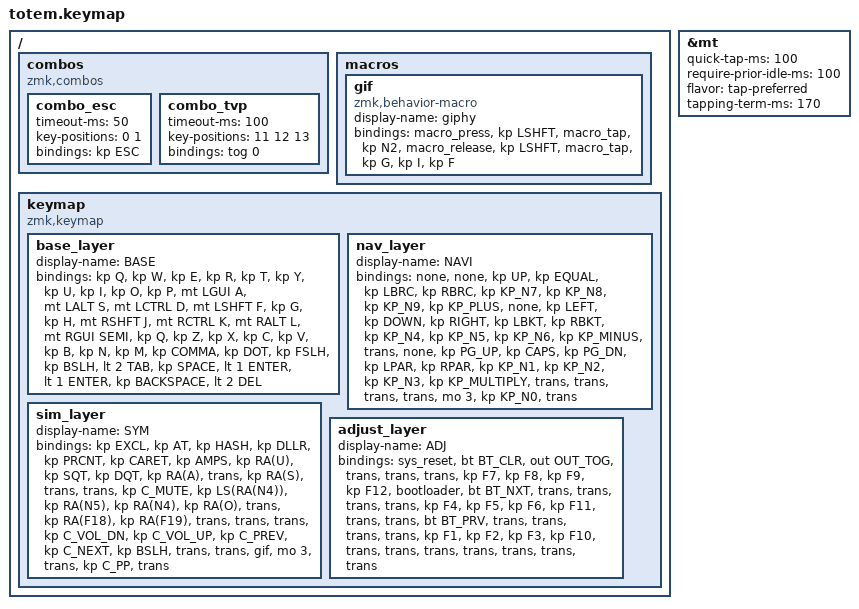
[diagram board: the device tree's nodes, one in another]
#include <behaviors.dtsi>
#include <dt-bindings/zmk/bt.h>
#include <dt-bindings/zmk/keys.h>
#include <dt-bindings/zmk/outputs.h>

#define BASE 0
#define NAV  1
#define SYM  2
#define ADJ  3
#define TVP1 4
#define TVP2 5

&mt {
    quick-tap-ms = <100>;
    require-prior-idle-ms = <100>;
    flavor = "tap-preferred";
    tapping-term-ms = <170>;
};

/ {
    combos {
        compatible = "zmk,combos";

        combo_esc {
            timeout-ms = <50>;
            key-positions = <0 1>;
            bindings = <&kp ESC>;
        };

        combo_tvp {
            timeout-ms = <100>;
            key-positions = <11 12 13>;
            bindings = <&tog 0>;
        };
    };

    macros {
        gif: gif {
            display-name = "giphy";
            compatible = "zmk,behavior-macro";
            #binding-cells = <0>;
            bindings =
                <&macro_press>,
                <&kp LSHFT>,
                <&macro_tap>,
                <&kp N2>,
                <&macro_release>,
                <&kp LSHFT>,
                <&macro_tap>,
                <&kp G &kp I &kp F>;
        };
    };

    keymap {
        compatible = "zmk,keymap";

        // ▄▄▄▄▄▄▄▄▄▄▄▄▄▄▄▄▄▄▄▄▄▄▄▄▄▄▄▄▄▄▄▄▄▄▄▄▄▄▄▄▄▄▄▄▄▄▄▄▄▄▄▄▄▄▄▄▄▄▄▄▄▄▄▄▄▄▄▄▄▄▄▄▄▄▄▄▄▄▄▄▄▄▄▄▄▄▄▄▄▄▄▄▄▄▄▄▄▄▄▄▄▄▄▄▄▄▄▄▄▄▄▄▄▄▄▄▄▄▄▄▄▄▄▄▄▄▄▄▄▄▄▄▄▄▄▄▄▄▄▄▄▄▄▄▄▄▄▄▄

        base_layer {
            // ┏━━━━━━━━━━━━━━━━━━━━━━━━━━━━━━━━━━━━━━━┓

            display-name = "BASE";

            // ┗━━━━━━━━━━━━━━━━━━━━━━━━━━━━━━━━━━━━━━━┛
            //             ┏━━━━━━━━━━━┳━━━━━━━━━━━┳━━━━━━━━━━━┳━━━━━━━━━━━┳━━━━━━━━━━━┓   ┏━━━━━━━━━━━┳━━━━━━━━━━━┳━━━━━━━━━━━┳━━━━━━━━━━━┳━━━━━━━━━━━┓
            //             ┃     Q     ┃     W     ┃     E     ┃     R     ┃     T     ┃   ┃     Y     ┃     U     ┃     I     ┃     O     ┃     P     ┃
            //             ┣━━━━━━━━━━━╋━━━━━━━━━━━╋━━━━━━━━━━━╋━━━━━━━━━━━╋━━━━━━━━━━━┫   ┣━━━━━━━━━━━╋━━━━━━━━━━━╋━━━━━━━━━━━╋━━━━━━━━━━━╋━━━━━━━━━━━┫
            //             ┃     A     ┃     S     ┃     D     ┃     F     ┃     G     ┃   ┃     H     ┃     J     ┃     K     ┃     L     ┃     ;     ┃
            // ┏━━━━━━━━━━━╋━━━━━━━━━━━╋━━━━━━━━━━━╋━━━━━━━━━━━╋━━━━━━━━━━━╋━━━━━━━━━━━┫   ┣━━━━━━━━━━━╋━━━━━━━━━━━╋━━━━━━━━━━━╋━━━━━━━━━━━╋━━━━━━━━━━━╋━━━━━━━━━━━┓
            // ┃     Q     ┃     Z     ┃     X     ┃     C     ┃     V     ┃     B     ┃   ┃     N     ┃     M     ┃     ,     ┃     .     ┃     /     ┃     \     ┃
            // ┗━━━━━━━━━━━┻━━━━━━━━━━━┻━━━━━━━━━━━╋━━━━━━━━━━━╋━━━━━━━━━━━╋━━━━━━━━━━━┫   ┣━━━━━━━━━━━╋━━━━━━━━━━━╋━━━━━━━━━━━╋━━━━━━━━━━━┻━━━━━━━━━━━┻━━━━━━━━━━━┛
            //                                     ┃    DEL    ┃    TAB    ┃    SPC    ┃   ┃   ENTER   ┃           ┃   BSPC    ┃
            //                                     ┗━━━━━━━━━━━┻━━━━━━━━━━━┻━━━━━━━━━━━┛   ┗━━━━━━━━━━━┻━━━━━━━━━━━┻━━━━━━━━━━━┛

            bindings = <
&kp Q  &kp W  &kp E  &kp R  &kp T  &kp Y  &kp U  &kp I  &kp O  &kp P  &mt LGUI A  &mt LALT S  &mt LCTRL D  &mt LSHFT F  &kp G  &kp H  &mt RSHFT J  &mt RCTRL K  &mt RALT L  &mt RGUI SEMI  &kp Q  &kp Z  &kp X  &kp C  &kp V  &kp B  &kp N  &kp M  &kp COMMA  &kp DOT  &kp FSLH  &kp BSLH  &lt 2 TAB  &kp SPACE  &lt 1 ENTER  &lt 1 ENTER  &kp BACKSPACE  &lt 2 DEL
            >;
        };

        // ▄▄▄▄▄▄▄▄▄▄▄▄▄▄▄▄▄▄▄▄▄▄▄▄▄▄▄▄▄▄▄▄▄▄▄▄▄▄▄▄▄▄▄▄▄▄▄▄▄▄▄▄▄▄▄▄▄▄▄▄▄▄▄▄▄▄▄▄▄▄▄▄▄▄▄▄▄▄▄▄▄▄▄▄▄▄▄▄▄▄▄▄▄▄▄▄▄▄▄▄▄▄▄▄▄▄▄▄▄▄▄▄▄▄▄▄▄▄▄▄▄▄▄▄▄▄▄▄▄▄▄▄▄▄▄▄▄▄▄▄▄▄▄▄▄▄▄▄▄

        nav_layer {
            // ┏━━━━━━━━━━━━━━━━━━━━━━━━━━━━━━━━━━━━━━━┓

            display-name = "NAVI";

            // ┗━━━━━━━━━━━━━━━━━━━━━━━━━━━━━━━━━━━━━━━┛
            //             ┏━━━━━━━━━━━┳━━━━━━━━━━━┳━━━━━━━━━━━┳━━━━━━━━━━━┳━━━━━━━━━━━┓   ┏━━━━━━━━━━━┳━━━━━━━━━━━┳━━━━━━━━━━━┳━━━━━━━━━━━┳━━━━━━━━━━━┓
            //             ┃           ┃           ┃     UP    ┃           ┃     {     ┃   ┃     }     ┃     7     ┃     8     ┃     9     ┃     +     ┃
            //             ┣━━━━━━━━━━━╋━━━━━━━━━━━╋━━━━━━━━━━━╋━━━━━━━━━━━╋━━━━━━━━━━━┫   ┣━━━━━━━━━━━╋━━━━━━━━━━━╋━━━━━━━━━━━╋━━━━━━━━━━━╋━━━━━━━━━━━┫
            //             ┃   SHIFT   ┃   LEFT    ┃    DOWN   ┃   RIGHT   ┃     [     ┃   ┃     ]     ┃     4     ┃     5     ┃     6     ┃     -     ┃
            // ┏━━━━━━━━━━━╋━━━━━━━━━━━╋━━━━━━━━━━━╋━━━━━━━━━━━╋━━━━━━━━━━━╋━━━━━━━━━━━┫   ┣━━━━━━━━━━━╋━━━━━━━━━━━╋━━━━━━━━━━━╋━━━━━━━━━━━╋━━━━━━━━━━━╋━━━━━━━━━━━┓
            // ┃           ┃           ┃   P UP    ┃  C LOCK   ┃  P DOWN   ┃     (     ┃   ┃     )     ┃     1     ┃     2     ┃     3     ┃     *     ┃           ┃
            // ┗━━━━━━━━━━━┻━━━━━━━━━━━┻━━━━━━━━━━━╋━━━━━━━━━━━╋━━━━━━━━━━━╋━━━━━━━━━━━┫   ┣━━━━━━━━━━━╋━━━━━━━━━━━╋━━━━━━━━━━━╋━━━━━━━━━━━┻━━━━━━━━━━━┻━━━━━━━━━━━┛
            //                                     ┃           ┃    TAB    ┃    SPC    ┃   ┃    DEL    ┃     0     ┃           ┃
            //                                     ┗━━━━━━━━━━━┻━━━━━━━━━━━┻━━━━━━━━━━━┛   ┗━━━━━━━━━━━┻━━━━━━━━━━━┻━━━━━━━━━━━┛

            bindings = <
&none  &none  &kp UP  &kp EQUAL  &kp LBRC  &kp RBRC  &kp KP_N7  &kp KP_N8  &kp KP_N9  &kp KP_PLUS  &none  &kp LEFT  &kp DOWN  &kp RIGHT  &kp LBKT  &kp RBKT  &kp KP_N4  &kp KP_N5  &kp KP_N6  &kp KP_MINUS  &trans  &none  &kp PG_UP  &kp CAPS  &kp PG_DN  &kp LPAR  &kp RPAR  &kp KP_N1  &kp KP_N2  &kp KP_N3  &kp KP_MULTIPLY  &trans  &trans  &trans  &trans  &mo 3  &kp KP_N0  &trans
            >;
        };

        // ▄▄▄▄▄▄▄▄▄▄▄▄▄▄▄▄▄▄▄▄▄▄▄▄▄▄▄▄▄▄▄▄▄▄▄▄▄▄▄▄▄▄▄▄▄▄▄▄▄▄▄▄▄▄▄▄▄▄▄▄▄▄▄▄▄▄▄▄▄▄▄▄▄▄▄▄▄▄▄▄▄▄▄▄▄▄▄▄▄▄▄▄▄▄▄▄▄▄▄▄▄▄▄▄▄▄▄▄▄▄▄▄▄▄▄▄▄▄▄▄▄▄▄▄▄▄▄▄▄▄▄▄▄▄▄▄▄▄▄▄▄▄▄▄▄▄▄▄▄

        sim_layer {
            // ┏━━━━━━━━━━━━━━━━━━━━━━━━━━━━━━━━━━━━━━━┓

            display-name = "SYM";

            // ┗━━━━━━━━━━━━━━━━━━━━━━━━━━━━━━━━━━━━━━━┛
            //             ┏━━━━━━━━━━━┳━━━━━━━━━━━┳━━━━━━━━━━━┳━━━━━━━━━━━┳━━━━━━━━━━━┓   ┏━━━━━━━━━━━┳━━━━━━━━━━━┳━━━━━━━━━━━┳━━━━━━━━━━━┳━━━━━━━━━━━┓
            //             ┃     !     ┃     @     ┃     #     ┃     $     ┃     %     ┃   ┃     ˆ     ┃     &     ┃     Ü     ┃     '     ┃     "     ┃
            //             ┣━━━━━━━━━━━╋━━━━━━━━━━━╋━━━━━━━━━━━╋━━━━━━━━━━━╋━━━━━━━━━━━┫   ┣━━━━━━━━━━━╋━━━━━━━━━━━╋━━━━━━━━━━━╋━━━━━━━━━━━╋━━━━━━━━━━━┫
            //             ┃     Ä     ┃           ┃    SZ     ┃           ┃           ┃   ┃   MUTE    ┃   YEN     ┃   EURO    ┃  POUND    ┃     Ö     ┃
            // ┏━━━━━━━━━━━╋━━━━━━━━━━━╋━━━━━━━━━━━╋━━━━━━━━━━━╋━━━━━━━━━━━╋━━━━━━━━━━━┫   ┣━━━━━━━━━━━╋━━━━━━━━━━━╋━━━━━━━━━━━╋━━━━━━━━━━━╋━━━━━━━━━━━╋━━━━━━━━━━━┓
            // ┃           ┃  EMAIL1   ┃  EMAIL2   ┃           ┃           ┃           ┃   ┃   VOL-    ┃   VOL+    ┃   LAST    ┃   NEXT    ┃     \     ┃           ┃
            // ┗━━━━━━━━━━━┻━━━━━━━━━━━┻━━━━━━━━━━━╋━━━━━━━━━━━╋━━━━━━━━━━━╋━━━━━━━━━━━┫   ┣━━━━━━━━━━━╋━━━━━━━━━━━╋━━━━━━━━━━━╋━━━━━━━━━━━┻━━━━━━━━━━━┻━━━━━━━━━━━┛
            //                                     ┃           ┃    GIF    ┃    ADJ    ┃   ┃           ┃           ┃           ┃
            //                                     ┗━━━━━━━━━━━┻━━━━━━━━━━━┻━━━━━━━━━━━┛   ┗━━━━━━━━━━━┻━━━━━━━━━━━┻━━━━━━━━━━━┛

            bindings = <
&kp EXCL  &kp AT  &kp HASH  &kp DLLR  &kp PRCNT  &kp CARET  &kp AMPS  &kp RA(U)  &kp SQT  &kp DQT  &kp RA(A)  &trans  &kp RA(S)  &trans  &trans  &kp C_MUTE  &kp LS(RA(N4))  &kp RA(N5)  &kp RA(N4)  &kp RA(O)  &trans  &kp RA(F18)  &kp RA(F19)  &trans  &trans  &trans  &kp C_VOL_DN  &kp C_VOL_UP  &kp C_PREV  &kp C_NEXT  &kp BSLH  &trans  &trans  &gif  &mo 3  &trans  &kp C_PP  &trans
            >;
        };

        // ▄▄▄▄▄▄▄▄▄▄▄▄▄▄▄▄▄▄▄▄▄▄▄▄▄▄▄▄▄▄▄▄▄▄▄▄▄▄▄▄▄▄▄▄▄▄▄▄▄▄▄▄▄▄▄▄▄▄▄▄▄▄▄▄▄▄▄▄▄▄▄▄▄▄▄▄▄▄▄▄▄▄▄▄▄▄▄▄▄▄▄▄▄▄▄▄▄▄▄▄▄▄▄▄▄▄▄▄▄▄▄▄▄▄▄▄▄▄▄▄▄▄▄▄▄▄▄▄▄▄▄▄▄▄▄▄▄▄▄▄▄▄▄▄▄▄▄▄▄

        adjust_layer {
            // ┏━━━━━━━━━━━━━━━━━━━━━━━━━━━━━━━━━━━━━━━┓

            display-name = "ADJ";

            // ┗━━━━━━━━━━━━━━━━━━━━━━━━━━━━━━━━━━━━━━━┛
            //             ┏━━━━━━━━━━━┳━━━━━━━━━━━┳━━━━━━━━━━━┳━━━━━━━━━━━┳━━━━━━━━━━━┓   ┏━━━━━━━━━━━┳━━━━━━━━━━━┳━━━━━━━━━━━┳━━━━━━━━━━━┳━━━━━━━━━━━┓
            //             ┃   RESET   ┃ BT CLEAR  ┃  OUT TOG  ┃           ┃           ┃   ┃           ┃    F7     ┃    F8     ┃    F9     ┃    F12    ┃
            //             ┣━━━━━━━━━━━╋━━━━━━━━━━━╋━━━━━━━━━━━╋━━━━━━━━━━━╋━━━━━━━━━━━┫   ┣━━━━━━━━━━━╋━━━━━━━━━━━╋━━━━━━━━━━━╋━━━━━━━━━━━╋━━━━━━━━━━━┫
            //             ┃ BOOTLOAD  ┃ BT NEXT   ┃           ┃           ┃           ┃   ┃           ┃    F4     ┃    F5     ┃    F6     ┃    F11    ┃
            // ┏━━━━━━━━━━━╋━━━━━━━━━━━╋━━━━━━━━━━━╋━━━━━━━━━━━╋━━━━━━━━━━━╋━━━━━━━━━━━┫   ┣━━━━━━━━━━━╋━━━━━━━━━━━╋━━━━━━━━━━━╋━━━━━━━━━━━╋━━━━━━━━━━━╋━━━━━━━━━━━┓
            // ┃           ┃           ┃ BT PREV   ┃           ┃           ┃           ┃   ┃           ┃    F1     ┃    F2     ┃    F3     ┃    F10    ┃           ┃
            // ┗━━━━━━━━━━━┻━━━━━━━━━━━┻━━━━━━━━━━━╋━━━━━━━━━━━╋━━━━━━━━━━━╋━━━━━━━━━━━┫   ┣━━━━━━━━━━━╋━━━━━━━━━━━╋━━━━━━━━━━━╋━━━━━━━━━━━┻━━━━━━━━━━━┻━━━━━━━━━━━┛
            //                                     ┃           ┃           ┃           ┃   ┃           ┃           ┃           ┃
            //                                     ┗━━━━━━━━━━━┻━━━━━━━━━━━┻━━━━━━━━━━━┛   ┗━━━━━━━━━━━┻━━━━━━━━━━━┻━━━━━━━━━━━┛

            bindings = <
&sys_reset  &bt BT_CLR  &out OUT_TOG  &trans  &trans  &trans  &kp F7  &kp F8  &kp F9  &kp F12  &bootloader  &bt BT_NXT  &trans  &trans  &trans  &trans  &kp F4  &kp F5  &kp F6  &kp F11  &trans  &trans  &bt BT_PRV  &trans  &trans  &trans  &trans  &kp F1  &kp F2  &kp F3  &kp F10  &trans  &trans  &trans  &trans  &trans  &trans  &trans
            >;
        };

        // ▄▄▄▄▄▄▄▄▄▄▄▄▄▄▄▄▄▄▄▄▄▄▄▄▄▄▄▄▄▄▄▄▄▄▄▄▄▄▄▄▄▄▄▄▄▄▄▄▄▄▄▄▄▄▄▄▄▄▄▄▄▄▄▄▄▄▄▄▄▄▄▄▄▄▄▄▄▄▄▄▄▄▄▄▄▄▄▄▄▄▄▄▄▄▄▄▄▄▄▄▄▄▄▄▄▄▄▄▄▄▄▄▄▄▄▄▄▄▄▄▄▄▄▄▄▄▄▄▄▄▄▄▄▄▄▄▄▄▄▄▄▄▄▄▄▄▄▄▄
        // ▄▄▄▄▄▄▄▄▄▄▄▄▄▄▄▄▄▄▄▄▄▄▄▄▄▄▄▄▄▄▄▄▄▄▄▄▄▄▄▄▄▄▄▄▄▄▄▄▄▄▄▄▄▄▄▄▄▄▄▄▄▄▄▄▄▄▄▄▄▄▄▄▄▄▄▄▄▄▄▄▄▄▄▄▄▄▄▄▄▄▄▄▄▄▄▄▄▄▄▄▄▄▄▄▄▄▄▄▄▄▄▄▄▄▄▄▄▄▄▄▄▄▄▄▄▄▄▄▄▄▄▄▄▄▄▄▄▄▄▄▄▄▄▄▄▄▄▄▄
    };
};
